# nrf51 register map
Vendor: Nordic Semiconductor; Series: nrf51; File version: 522
CPU: CM0 r3p1, little endian, no MPU, no FPU, 2 interrupt priority bits
Registers are 32-bit, read-write, reset 0x0 unless marked. A register's access mark holds for its fields unless they carry their own. Offsets are from the block's base; [hi:lo] are bit positions; 'fields as' and 'values as' point back to an identical list.

## RNG — Random Number Generator.
Base 0x4000D000
0x00 TASKS_START wo — Start the random number generator.
0x04 TASKS_STOP wo — Stop the random number generator.
0x100 EVENTS_VALRDY — New random number generated and written to VALUE register.
0x200 SHORTS — Shortcuts for the RNG.
  [0] VALRDY_STOP — Shortcut between VALRDY event and STOP task.
    0=Disabled (Shortcut disabled.); 1=Enabled (Shortcut enabled.)
0x304 INTENSET — Interrupt enable set register
  [0] VALRDY — Enable interrupt on VALRDY event.
    on read: 0=Disabled (Interrupt disabled.); 1=Enabled (Interrupt enabled.) | on write: 1=Set (Enable interrupt on write.)
0x308 INTENCLR — Interrupt enable clear register
  [0] VALRDY — Disable interrupt on VALRDY event.
    on read: 0=Disabled (Interrupt disabled.); 1=Enabled (Interrupt enabled.) | on write: 1=Clear (Disable interrupt on write.)
0x504 CONFIG — Configuration register.
  [0] DERCEN — Digital error correction enable.
    0=Disabled (Digital error correction disabled.); 1=Enabled (Digital error correction enabled.)
0x508 VALUE ro — RNG random number.
  [7:0] VALUE — Generated random number.
0xFFC POWER — Peripheral power control.
  [0] POWER
    0=Disabled (Module power disabled.); 1=Enabled (Module power enabled.)

## ECB — AES ECB Mode Encryption.
Base 0x4000E000
0x00 TASKS_STARTECB wo — Start ECB block encrypt. If a crypto operation is running, this will not initiate a new encryption and the ERRORECB event will be triggered.
0x04 TASKS_STOPECB wo — Stop current ECB encryption. If a crypto operation is running, this will will trigger the ERRORECB event.
0x100 EVENTS_ENDECB — ECB block encrypt complete.
0x104 EVENTS_ERRORECB — ECB block encrypt aborted due to a STOPECB task or due to an error.
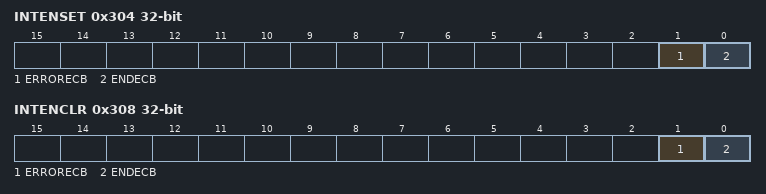
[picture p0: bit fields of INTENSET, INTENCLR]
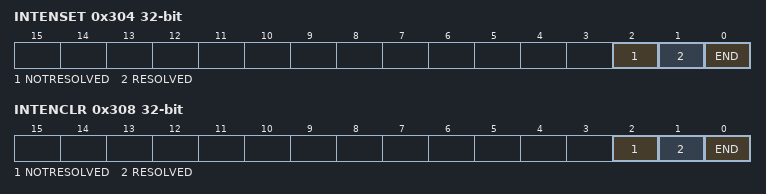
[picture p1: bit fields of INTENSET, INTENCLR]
0x304 INTENSET — Interrupt enable set register.
  [1] ERRORECB — Enable interrupt on ERRORECB event.
    on read: 0=Disabled (Interrupt disabled.); 1=Enabled (Interrupt enabled.) | on write: 1=Set (Enable interrupt on write.)
  [0] ENDECB — Enable interrupt on ENDECB event.
    values as ERRORECB
0x308 INTENCLR — Interrupt enable clear register.
  [1] ERRORECB — Disable interrupt on ERRORECB event.
    on read: 0=Disabled (Interrupt disabled.); 1=Enabled (Interrupt enabled.) | on write: 1=Clear (Disable interrupt on write.)
  [0] ENDECB — Disable interrupt on ENDECB event.
    values as ERRORECB
0x504 ECBDATAPTR — ECB block encrypt memory pointer.
0xFFC POWER — Peripheral power control.
  [0] POWER
    0=Disabled (Module power disabled.); 1=Enabled (Module power enabled.)

## AAR — Accelerated Address Resolver.
Base 0x4000F000
0x00 TASKS_START wo — Start resolving addresses based on IRKs specified in the IRK data structure.
0x08 TASKS_STOP wo — Stop resolving addresses.
0x100 EVENTS_END — Address resolution procedure completed.
0x104 EVENTS_RESOLVED — Address resolved.
0x108 EVENTS_NOTRESOLVED — Address not resolved.
0x304 INTENSET — Interrupt enable set register.
  [all] fields
    on read: 0=Disabled (Interrupt disabled.); 1=Enabled (Interrupt enabled.) | on write: 1=Set (Enable interrupt on write.)
  [2] NOTRESOLVED — Enable interrupt on NOTRESOLVED event.
  [1] RESOLVED — Enable interrupt on RESOLVED event.
  [0] END — Enable interrupt on END event.
0x308 INTENCLR — Interrupt enable clear register.
  [all] fields
    on read: 0=Disabled (Interrupt disabled.); 1=Enabled (Interrupt enabled.) | on write: 1=Clear (Disable interrupt on write.)
  [2] NOTRESOLVED — Disable interrupt on NOTRESOLVED event.
  [1] RESOLVED — Disable interrupt on RESOLVED event.
  [0] END — Disable interrupt on ENDKSGEN event.
0x400 STATUS ro — Resolution status.
  [3:0] STATUS — The IRK used last time an address was resolved.
0x500 ENABLE — Enable AAR.
  [1:0] ENABLE
    0=Disabled AAR; 3=Enabled (Enable AAR.)
0x504 NIRK reset 0x1 — Number of Identity root Keys in the IRK data structure.
  [4:0] NIRK
0x508 IRKPTR — Pointer to the IRK data structure.
0x510 ADDRPTR — Pointer to the resolvable address (6 bytes).
0x514 SCRATCHPTR — Pointer to a scratch data area used for temporary storage during resolution. A minimum of 3 bytes must be reserved.
0xFFC POWER — Peripheral power control.
  [0] POWER
    0=Disabled (Module power disabled.); 1=Enabled (Module power enabled.)
